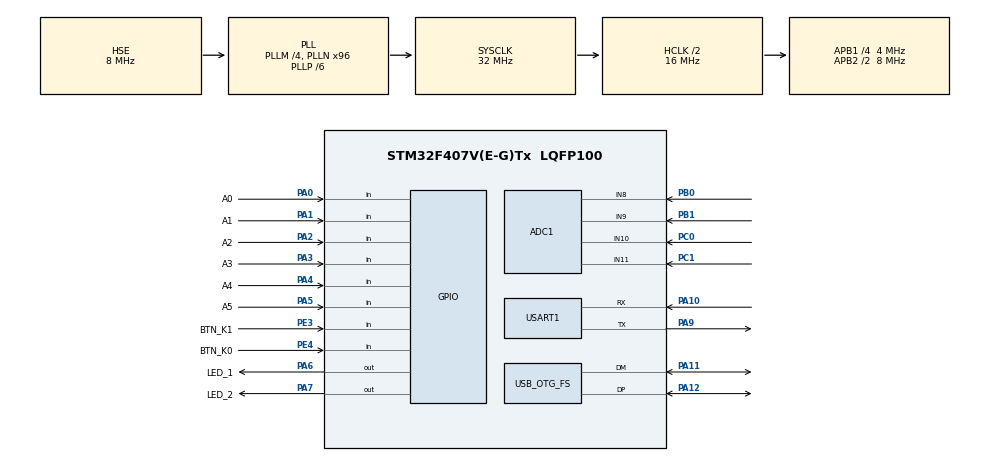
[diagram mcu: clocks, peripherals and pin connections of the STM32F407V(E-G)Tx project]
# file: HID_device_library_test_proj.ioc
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ADC1.Channel-0\#ChannelRegularConversion=ADC_CHANNEL_8
ADC1.NbrOfConversionFlag=1
ADC1.Rank-0\#ChannelRegularConversion=1
ADC1.SamplingTime-0\#ChannelRegularConversion=ADC_SAMPLETIME_3CYCLES
ADC1.master=1
Mcu.Family=STM32F4
Mcu.Name=STM32F407V(E-G)Tx
Mcu.Package=LQFP100
NVIC.OTG_FS_IRQn=true\:0\:0\:false\:false\:true\:false\:true\:true
NVIC.PriorityGroup=NVIC_PRIORITYGROUP_4
PA0-WKUP.GPIO_Label=A0
PA0-WKUP.Signal=GPIO_Input
PA1.GPIO_Label=A1
PA1.Signal=GPIO_Input
PA10.Mode=Asynchronous
PA10.Signal=USART1_RX
PA11.Mode=Device_Only
PA11.Signal=USB_OTG_FS_DM
PA12.Mode=Device_Only
PA12.Signal=USB_OTG_FS_DP
PA13.Mode=Serial_Wire
PA13.Signal=SYS_JTMS-SWDIO
PA14.Mode=Serial_Wire
PA14.Signal=SYS_JTCK-SWCLK
PA2.GPIO_Label=A2
PA2.Signal=GPIO_Input
PA3.GPIO_Label=A3
PA3.Signal=GPIO_Input
PA4.GPIO_Label=A4
PA4.Signal=GPIO_Input
PA5.GPIO_Label=A5
PA5.Signal=GPIO_Input
PA6.GPIO_Label=LED_1
PA6.Signal=GPIO_Output
PA7.GPIO_Label=LED_2
PA7.Signal=GPIO_Output
PA9.Mode=Asynchronous
PA9.Signal=USART1_TX
PB0.Signal=ADCx_IN8
PB1.Signal=ADCx_IN9
PC0.Signal=ADCx_IN10
PC1.Signal=ADCx_IN11
PC14-OSC32_IN.Mode=LSE-External-Oscillator
PC14-OSC32_IN.Signal=RCC_OSC32_IN
PC15-OSC32_OUT.Mode=LSE-External-Oscillator
PC15-OSC32_OUT.Signal=RCC_OSC32_OUT
PE3.GPIO_Label=BTN_K1
PE3.GPIO_PuPd=GPIO_PULLUP
PE3.Signal=GPIO_Input
PE4.GPIO_Label=BTN_K0
PE4.GPIO_PuPd=GPIO_PULLUP
PE4.Signal=GPIO_Input
PH0-OSC_IN.Mode=HSE-External-Oscillator
PH0-OSC_IN.Signal=RCC_OSC_IN
PH1-OSC_OUT.Mode=HSE-External-Oscillator
PH1-OSC_OUT.Signal=RCC_OSC_OUT
ProjectManager.HeapSize=0x200
ProjectManager.StackSize=0x400
ProjectManager.TargetToolchain=STM32CubeIDE
RCC.48MHZClocksFreq_Value=48000000
RCC.AHBCLKDivider=RCC_SYSCLK_DIV2
RCC.AHBFreq_Value=16000000
RCC.APB1CLKDivider=RCC_HCLK_DIV4
RCC.APB1Freq_Value=4000000
RCC.APB1TimFreq_Value=8000000
RCC.APB2CLKDivider=RCC_HCLK_DIV2
RCC.APB2Freq_Value=8000000
RCC.APB2TimFreq_Value=16000000
RCC.CortexFreq_Value=16000000
RCC.HCLKFreq_Value=16000000
RCC.HSE_VALUE=8000000
RCC.HSI_VALUE=16000000
RCC.PLLM=4
RCC.PLLN=96
RCC.PLLP=RCC_PLLP_DIV6
RCC.SYSCLKFreq_VALUE=32000000
RCC.SYSCLKSource=RCC_SYSCLKSOURCE_PLLCLK
RCC.VCOOutputFreq_Value=192000000
SH.ADCx_IN10.0=ADC1_IN10,IN10
SH.ADCx_IN11.0=ADC1_IN11,IN11
SH.ADCx_IN8.0=ADC1_IN8,IN8
SH.ADCx_IN9.0=ADC1_IN9,IN9
USART1.VirtualMode=VM_ASYNC
USB_DEVICE.CLASS_NAME_FS=CUSTOM_HID
USB_DEVICE.CUSTOM_HID_FS_BINTERVAL=0x20
USB_DEVICE.LANGID_STRING-CUSTOM_HID_FS=1041
USB_DEVICE.MANUFACTURER_STRING-CUSTOM_HID_FS=Nemuro
USB_DEVICE.PID_CUSTOMHID_FS=0xa004
USB_DEVICE.PRODUCT_STRING_CUSTOMHID_FS=HID_Device_debugBoard_F4VE
USB_DEVICE.USBD_CUSTOMHID_OUTREPORT_BUF_SIZE-CUSTOM_HID_FS=64
USB_DEVICE.USBD_CUSTOM_HID_REPORT_DESC_SIZE-CUSTOM_HID_FS=49
USB_DEVICE.VID-CUSTOM_HID_FS=6666
USB_DEVICE.VirtualMode-CUSTOM_HID_FS=CustomHid
USB_DEVICE.VirtualModeFS=Custom_Hid_FS
USB_OTG_FS.VirtualMode=Device_Only
VP_USB_DEVICE_VS_USB_DEVICE_CUSTOM_HID_FS.Mode=CUSTOM_HID_FS
board=custom

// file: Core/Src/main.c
/* USER CODE BEGIN Header */
/**
  ******************************************************************************
  * @file           : main.c
  * @brief          : Main program body
  ******************************************************************************
  * @attention
  *
  * Copyright (c) 2023 STMicroelectronics.
  * All rights reserved.
  *
  * This software is licensed under terms that can be found in the LICENSE file
  * in the root directory of this software component.
  * If no LICENSE file comes with this software, it is provided AS-IS.
  *
  ******************************************************************************
  */
/* USER CODE END Header */
#include "main.h"
#include "adc.h"
#include "usart.h"
#include "usb_device.h"
#include "gpio.h"

/* USER CODE BEGIN Includes */
#include "../Alt/alt_main.h"
/* USER CODE END Includes */

void SystemClock_Config(void);

int main(void)
{

  /* MCU Configuration--------------------------------------------------------*/

  /* Reset of all peripherals, Initializes the Flash interface and the Systick. */
  HAL_Init();

  /* Configure the system clock */
  SystemClock_Config();

  /* Initialize all configured peripherals */
  MX_GPIO_Init();
  MX_USB_DEVICE_Init();
  MX_ADC1_Init();
  MX_USART1_UART_Init();

  /* Infinite loop */
  /* USER CODE BEGIN WHILE */
  while (1)
  {
    alt_main();
    /* USER CODE END WHILE */

  }
}

void SystemClock_Config(void)
{
  RCC_OscInitTypeDef RCC_OscInitStruct = {0};
  RCC_ClkInitTypeDef RCC_ClkInitStruct = {0};

  /** Configure the main internal regulator output voltage
  */
  __HAL_RCC_PWR_CLK_ENABLE();
  __HAL_PWR_VOLTAGESCALING_CONFIG(PWR_REGULATOR_VOLTAGE_SCALE1);

  /** Initializes the RCC Oscillators according to the specified parameters
  * in the RCC_OscInitTypeDef structure.
  */
  RCC_OscInitStruct.OscillatorType = RCC_OSCILLATORTYPE_HSE;
  RCC_OscInitStruct.HSEState = RCC_HSE_ON;
  RCC_OscInitStruct.PLL.PLLState = RCC_PLL_ON;
  RCC_OscInitStruct.PLL.PLLSource = RCC_PLLSOURCE_HSE;
  RCC_OscInitStruct.PLL.PLLM = 4;
  RCC_OscInitStruct.PLL.PLLN = 96;
  RCC_OscInitStruct.PLL.PLLP = RCC_PLLP_DIV6;
  RCC_OscInitStruct.PLL.PLLQ = 4;
  if (HAL_RCC_OscConfig(&RCC_OscInitStruct) != HAL_OK)
  {
    Error_Handler();
  }

  /** Initializes the CPU, AHB and APB buses clocks
  */
  RCC_ClkInitStruct.ClockType = RCC_CLOCKTYPE_HCLK|RCC_CLOCKTYPE_SYSCLK
                              |RCC_CLOCKTYPE_PCLK1|RCC_CLOCKTYPE_PCLK2;
  RCC_ClkInitStruct.SYSCLKSource = RCC_SYSCLKSOURCE_PLLCLK;
  RCC_ClkInitStruct.AHBCLKDivider = RCC_SYSCLK_DIV2;
  RCC_ClkInitStruct.APB1CLKDivider = RCC_HCLK_DIV4;
  RCC_ClkInitStruct.APB2CLKDivider = RCC_HCLK_DIV2;

  if (HAL_RCC_ClockConfig(&RCC_ClkInitStruct, FLASH_LATENCY_0) != HAL_OK)
  {
    Error_Handler();
  }
}

void Error_Handler(void)
{
  __disable_irq();
  while (1)
  {
  }
}
